# WS53 register map
File version: 0.1.0-experimental
Registers are 32-bit, read-write, no defined reset value unless marked. A register's access mark holds for its fields unless they carry their own. Offsets are from the block's base; lines under a group give offsets from that group; [hi:lo] are bit positions; {n}, {i} and the like mark numbered series; 'fields as' and 'values as' point back to an identical list; <NAME> marks a mode.

## Memory map
0x52000000 M_CRG size 0x1602
0x52002000 TIMER size 0x220
0x52004100 MCU_DIAG size 0x12C
0x52008000 PINMUX_MCU size 0x5C
0x52010000 SPACC size 0xD200
0x52022000 KM size 0x1B38
0x52024000 TRNG size 0x17C
0x52030000 I2S size 0xC4
0x52060000 SDIO size 0x25C
0x52070000 MDMA size 0x200
0x52080000 UART1 size 0x64
0x52081000 UART0 size 0x64
0x52082000 PWM size 0x51C
0x52083000 I2C0 size 0xC8
0x52084000 I2C1 size 0xC8
0x52087000 SPI0 size 0xFC
0x5208A000 ADC size 0x100
0x5208D000 QSPI1 size 0xFC
0x5208F800 FAMA_STATUS size 0x50
0x53000000 SFC_CFG size 0x1650
0x57000000 GLB_CTL size 0xCC
0x57000200 TCXO size 0x14
0x57008600 AUDIO_CMU size 0x4
0x5700C000 GPIO0 size 0x38
0x57010000 GPIO2 size 0x38
0x57014000 UART2 size 0x64
0x57024000 EFUSE size 0xA00
0x57028000 GPIO1 size 0x38
0x57029100 RTC0 size 0x20
0x57029200 RTC1 size 0x20
0x5702B000 WDT size 0x2C
0x57030000 SYSTEM_MEMORY size 0x970
0x57036000 PINMUX_AON size 0xCC
0x5703A000 PINMUX_TZPC size 0x17C
0x59006300 TSENSOR size 0x38

## Interrupts
26 APP_INT0 (M_CRG)
27 APP_INT1 (M_CRG)
29 SGPIO_INT (GPIO2)
33 GPIO_1 (GPIO1)
34 GPIO_0 (GPIO0)
39 UART_0 (UART0)
41 UART_1 (UART1)
42 UART_2 (UART2)
43 QSPI0_2CS (QSPI1)
46 SDIO
49 RTC_0 (RTC0)
50 RTC_1 (RTC1)
53 TIMER_0 (TIMER)
54 TIMER_1 (TIMER)
58 M_DMA (MDMA)
59 SEC_INT1 (SPACC)
61 SEC_INT3 (KM)
62 I2C_0 (I2C0)
63 I2C_1 (I2C1)
65 SPI_3 (SPI0)
67 I2S
71 PWM_ABNOR (PWM)
72 PWM_CFG (PWM)
80 LSADC (ADC)

## TIMER
Base 0x52002000
0x100 TIMER_LOAD_COUNT0
  [31:0] LOAD_COUNT — Full32-bit requested reload. WS53 A-board reads after writes return written_value OR 0xF; low read bits are not a retained write value. Effective sub16-tick timing and POR readback unqualified; see ws53-timer-load-hil.json
0x108 TIMER_CURRENT_VALUE0 ro
  [31:0] CURRENT_VALUE — Timer 0 current count value
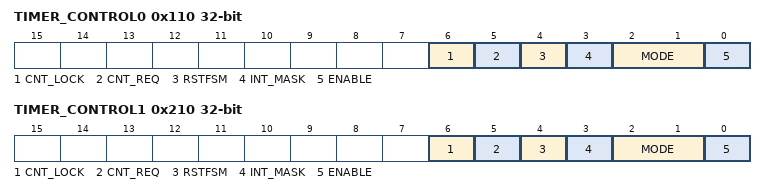
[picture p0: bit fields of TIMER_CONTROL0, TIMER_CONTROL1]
0x110 TIMER_CONTROL0 access per field
  [6] CNT_LOCK ro — Current-count latch valid (TIMER_V150): set by HW after a cnt_req snapshot completes; poll until 1 before reading the current-value register.
  [5] CNT_REQ rw — Current-count latch request (TIMER_V150): write 1 to snapshot the live down-counter into the current-value register; the HW asserts cnt_lock when the snapshot is ready. Required to read a fresh count on silicon (the current-value register is a latch, not a live counter).
  [4] RSTFSM wo — Reset FSM: 1=reset timer FSM
  [3] INT_MASK rw — Interrupt mask: 0=unmasked; 1=masked
  [2:1] MODE rw — Timer mode (TIMER_V150, per vendor control_reg_mode_v150_t): 0=one-shot; 1=periodic; 3=free-run (2 is a one-shot alias)
    0=One-shot mode; 1=Periodic mode; 3=Free-running mode
  [0] ENABLE rw — Timer enable: 0=disabled; 1=enabled
0x114 TIMER_EOI0 wo
  [0] EOI write-1-clears — Write one to acknowledge channel 0; read semantics unverified, no read API
0x118 TIMER_RAW_INTR0 ro
  [0] RAW_INTR — Raw interrupt status
0x11C TIMER_MASKED_INTR0 ro
  [0] PENDING
0x200 TIMER_LOAD_COUNT1
  fields as TIMER_LOAD_COUNT0
0x208 TIMER_CURRENT_VALUE1 ro
  [31:0] CURRENT_VALUE — Timer 0 current count value
0x210 TIMER_CONTROL1 access per field
  fields as TIMER_CONTROL0
0x214 TIMER_EOI1 wo
  [0] EOI write-1-clears — Write one to acknowledge channel 1; read semantics unverified, no read API
0x218 TIMER_RAW_INTR1 ro
  [0] RAW_INTR — Raw interrupt status
0x21C TIMER_MASKED_INTR1 ro
  [0] PENDING

## MCU_DIAG
Base 0x52004100
0x00 MONITOR_SELECT
  [0] SELECT
0x04 TRACE_SAVE_SELECT
  [0] SELECT
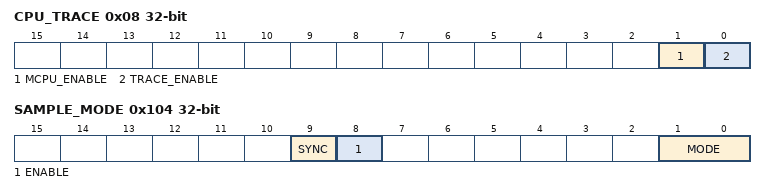
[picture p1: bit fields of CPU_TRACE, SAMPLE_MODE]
0x08 CPU_TRACE
  [1] MCPU_ENABLE, [0] TRACE_ENABLE
0x0C MONITOR_CLOCK — Clock enable mask; SDK trace writes 0x1ff, individual clock ownership needs audit
  [8:0] MASK
0x100 SAMPLE_SELECT — Opaque source selection; ADC SDK writes 6. Other selectors are not defined here
  [31:0] VALUE
0x104 SAMPLE_MODE
  [9] SYNC
  [8] ENABLE
  [1:0] MODE
    0=ONCE; 1=REPEAT
0x108 LENGTH_LOW
  [15:0] VALUE
0x10C LENGTH_HIGH
  [15:0] VALUE
0x110 START_LOW
  [15:0] VALUE
0x114 START_HIGH
  [15:0] VALUE
0x118 END_LOW
  [15:0] VALUE
0x11C END_HIGH
  [15:0] VALUE
0x120 DONE_ADDRESS_LOW ro
  [15:0] VALUE
0x124 DONE_ADDRESS_HIGH ro
  [15:0] VALUE
0x128 SAMPLE_DONE ro — ADC v155 struct and sample_done_data_t; CPU-trace port's DONE macro at +0x120 conflicts and is not used
  [0] DONE
